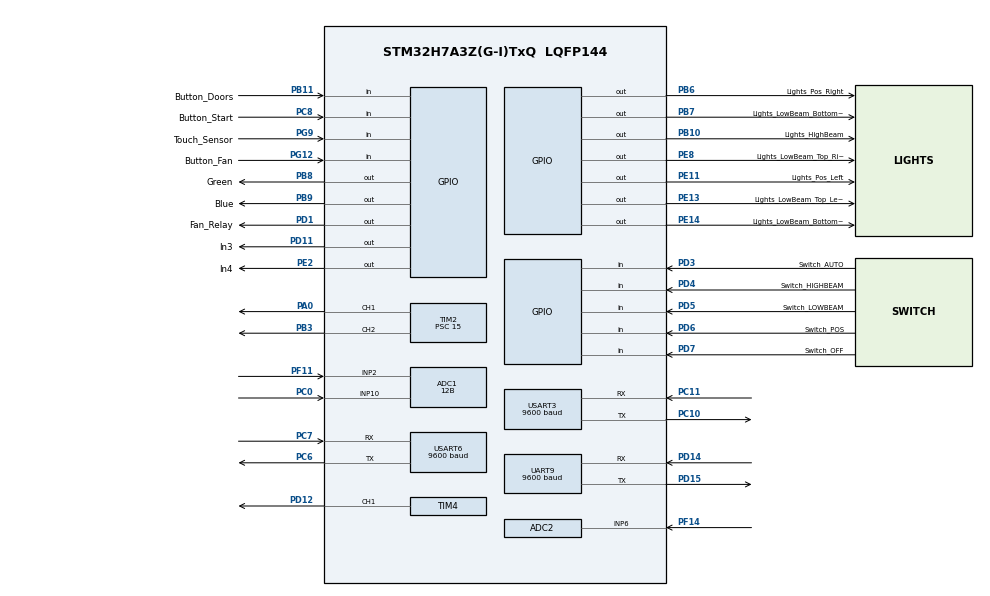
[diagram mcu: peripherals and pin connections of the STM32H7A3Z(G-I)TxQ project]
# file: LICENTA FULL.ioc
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ADC1.Channel-1\#ChannelRegularConversion=ADC_CHANNEL_2
ADC1.Channel-2\#ChannelRegularConversion=ADC_CHANNEL_10
ADC1.ContinuousConvMode=DISABLE
ADC1.ConversionDataManagement=ADC_CONVERSIONDATA_DMA_CIRCULAR
ADC1.NbrOfConversion=2
ADC1.NbrOfConversionFlag=1
ADC1.OffsetNumber-1\#ChannelRegularConversion=ADC_OFFSET_NONE
ADC1.OffsetNumber-2\#ChannelRegularConversion=ADC_OFFSET_NONE
ADC1.OffsetSignedSaturation-1\#ChannelRegularConversion=DISABLE
ADC1.Rank-1\#ChannelRegularConversion=1
ADC1.Rank-2\#ChannelRegularConversion=2
ADC1.Resolution=ADC_RESOLUTION_12B
ADC1.SamplingTime-1\#ChannelRegularConversion=ADC_SAMPLETIME_1CYCLE_5
ADC1.SamplingTime-2\#ChannelRegularConversion=ADC_SAMPLETIME_1CYCLE_5
ADC1.master=1
ADC2.Channel-0\#ChannelRegularConversion=ADC_CHANNEL_6
ADC2.ContinuousConvMode=ENABLE
ADC2.NbrOfConversion=1
ADC2.NbrOfConversionFlag=1
ADC2.OffsetNumber-0\#ChannelRegularConversion=ADC_OFFSET_NONE
ADC2.OffsetSignedSaturation-0\#ChannelRegularConversion=DISABLE
ADC2.Rank-0\#ChannelRegularConversion=1
ADC2.Resolution=ADC_RESOLUTION_12B
ADC2.SamplingTime-0\#ChannelRegularConversion=ADC_SAMPLETIME_1CYCLE_5
Dma.ADC1.0.Direction=DMA_PERIPH_TO_MEMORY
Dma.ADC1.0.EventEnable=DISABLE
Dma.ADC1.0.FIFOMode=DMA_FIFOMODE_DISABLE
Dma.ADC1.0.Instance=DMA1_Stream1
Dma.ADC1.0.MemDataAlignment=DMA_MDATAALIGN_HALFWORD
Dma.ADC1.0.MemInc=DMA_MINC_ENABLE
Dma.ADC1.0.Mode=DMA_CIRCULAR
Dma.ADC1.0.PeriphDataAlignment=DMA_PDATAALIGN_HALFWORD
Dma.ADC1.0.PeriphInc=DMA_PINC_DISABLE
Dma.ADC1.0.Polarity=HAL_DMAMUX_REQ_GEN_RISING
Dma.ADC1.0.Priority=DMA_PRIORITY_LOW
Dma.ADC1.0.RequestNumber=1
Dma.ADC1.0.SignalID=NONE
Dma.ADC1.0.SyncEnable=DISABLE
Dma.ADC1.0.SyncPolarity=HAL_DMAMUX_SYNC_NO_EVENT
Dma.ADC1.0.SyncRequestNumber=1
Dma.ADC1.0.SyncSignalID=NONE
Dma.Request0=ADC1
Dma.Request1=USART3_RX
Dma.Request2=USART6_RX
Dma.USART3_RX.1.Direction=DMA_PERIPH_TO_MEMORY
Dma.USART3_RX.1.EventEnable=DISABLE
Dma.USART3_RX.1.FIFOMode=DMA_FIFOMODE_DISABLE
Dma.USART3_RX.1.Instance=DMA1_Stream2
Dma.USART3_RX.1.MemDataAlignment=DMA_MDATAALIGN_BYTE
Dma.USART3_RX.1.MemInc=DMA_MINC_ENABLE
Dma.USART3_RX.1.Mode=DMA_NORMAL
Dma.USART3_RX.1.PeriphDataAlignment=DMA_PDATAALIGN_BYTE
Dma.USART3_RX.1.PeriphInc=DMA_PINC_DISABLE
Dma.USART3_RX.1.Polarity=HAL_DMAMUX_REQ_GEN_RISING
Dma.USART3_RX.1.Priority=DMA_PRIORITY_LOW
Dma.USART3_RX.1.RequestNumber=1
Dma.USART3_RX.1.SignalID=NONE
Dma.USART3_RX.1.SyncEnable=DISABLE
Dma.USART3_RX.1.SyncPolarity=HAL_DMAMUX_SYNC_NO_EVENT
Dma.USART3_RX.1.SyncRequestNumber=1
Dma.USART3_RX.1.SyncSignalID=NONE
Dma.USART6_RX.2.Direction=DMA_PERIPH_TO_MEMORY
Dma.USART6_RX.2.EventEnable=DISABLE
Dma.USART6_RX.2.FIFOMode=DMA_FIFOMODE_DISABLE
Dma.USART6_RX.2.Instance=DMA1_Stream0
Dma.USART6_RX.2.MemDataAlignment=DMA_MDATAALIGN_BYTE
Dma.USART6_RX.2.MemInc=DMA_MINC_ENABLE
Dma.USART6_RX.2.Mode=DMA_CIRCULAR
Dma.USART6_RX.2.PeriphDataAlignment=DMA_PDATAALIGN_BYTE
Dma.USART6_RX.2.PeriphInc=DMA_PINC_DISABLE
Dma.USART6_RX.2.Polarity=HAL_DMAMUX_REQ_GEN_RISING
Dma.USART6_RX.2.Priority=DMA_PRIORITY_LOW
Dma.USART6_RX.2.RequestNumber=1
Dma.USART6_RX.2.SignalID=NONE
Dma.USART6_RX.2.SyncEnable=DISABLE
Dma.USART6_RX.2.SyncPolarity=HAL_DMAMUX_SYNC_NO_EVENT
Dma.USART6_RX.2.SyncRequestNumber=1
Dma.USART6_RX.2.SyncSignalID=NONE
FREERTOS.Tasks01=defaultTask,24,128,StartDefaultTask,Default,NULL,Dynamic,NULL,NULL
Mcu.Family=STM32H7
Mcu.Name=STM32H7A3Z(G-I)TxQ
Mcu.Package=LQFP144
NVIC.DMA1_Stream0_IRQn=true\:5\:0\:false\:false\:true\:true\:false\:true\:true
NVIC.DMA1_Stream1_IRQn=true\:5\:0\:false\:false\:true\:true\:false\:true\:true
NVIC.DMA1_Stream2_IRQn=true\:5\:0\:false\:false\:true\:true\:false\:true\:true
NVIC.PriorityGroup=NVIC_PRIORITYGROUP_4
NVIC.USART3_IRQn=true\:5\:0\:false\:false\:true\:true\:true\:true\:true
PA0.Signal=S_TIM2_CH1_ETR
PB10.GPIO_Label=Lights_HighBeam
PB10.Signal=GPIO_Output
PB11.GPIO_Label=Button_Doors
PB11.GPIO_PuPd=GPIO_PULLDOWN
PB11.Signal=GPIO_Input
PB3.Signal=S_TIM2_CH2
PB6.GPIO_Label=Lights_Pos_Right
PB6.Signal=GPIO_Output
PB7.GPIO_Label=Lights_LowBeam_Bottom_Right
PB7.Signal=GPIO_Output
PB8.GPIO_Label=Green
PB8.Signal=GPIO_Output
PB9.GPIO_Label=Blue
PB9.Signal=GPIO_Output
PC0.Signal=ADCx_INP10
PC10.Mode=Asynchronous
PC10.Signal=USART3_TX
PC11.Mode=Asynchronous
PC11.Signal=USART3_RX
PC6.Mode=Asynchronous
PC6.Signal=USART6_TX
PC7.Mode=Asynchronous
PC7.Signal=USART6_RX
PC8.GPIO_Label=Button_Start
PC8.GPIO_PuPd=GPIO_PULLDOWN
PC8.Signal=GPIO_Input
PD1.GPIO_Label=Fan_Relay
PD1.Signal=GPIO_Output
PD11.GPIO_Label=In3
PD11.Signal=GPIO_Output
PD12.Signal=S_TIM4_CH1
PD14.Mode=Asynchronous
PD14.Signal=UART9_RX
PD15.Mode=Asynchronous
PD15.Signal=UART9_TX
PD3.GPIO_Label=Switch_AUTO
PD3.GPIO_PuPd=GPIO_PULLDOWN
PD3.Signal=GPIO_Input
PD4.GPIO_Label=Switch_HIGHBEAM
PD4.GPIO_PuPd=GPIO_PULLDOWN
PD4.Signal=GPIO_Input
PD5.GPIO_Label=Switch_LOWBEAM
PD5.GPIO_PuPd=GPIO_PULLDOWN
PD5.Signal=GPIO_Input
PD6.GPIO_Label=Switch_POS
PD6.GPIO_PuPd=GPIO_PULLDOWN
PD6.Signal=GPIO_Input
PD7.GPIO_Label=Switch_OFF
PD7.GPIO_PuPd=GPIO_PULLDOWN
PD7.Signal=GPIO_Input
PE11.GPIO_Label=Lights_Pos_Left
PE11.Signal=GPIO_Output
PE13.GPIO_Label=Lights_LowBeam_Top_Left
PE13.Signal=GPIO_Output
PE14.GPIO_Label=Lights_LowBeam_Bottom_Left
PE14.Signal=GPIO_Output
PE2.GPIO_Label=In4
PE2.Signal=GPIO_Output
PE8.GPIO_Label=Lights_LowBeam_Top_Right
PE8.Signal=GPIO_Output
PF11.Mode=IN2-Single-Ended
PF11.Signal=ADC1_INP2
PF14.Mode=IN6-Single-Ended
PF14.Signal=ADC2_INP6
PG12.GPIO_Label=Button_Fan
PG12.GPIO_PuPd=GPIO_PULLDOWN
PG12.Signal=GPIO_Input
PG9.GPIO_Label=Touch_Sensor
PG9.Signal=GPIO_Input
PH0-OSC_IN.Mode=HSE-External-Oscillator
PH0-OSC_IN.Signal=RCC_OSC_IN
PH1-OSC_OUT.Mode=HSE-External-Oscillator
PH1-OSC_OUT.Signal=RCC_OSC_OUT
ProjectManager.HeapSize=0x200
ProjectManager.StackSize=0x400
ProjectManager.TargetToolchain=STM32CubeIDE
RCC.ADCFreq_Value=42666666.666666664
RCC.APB1Freq_Value=16000000
RCC.APB2Freq_Value=16000000
RCC.APB3Freq_Value=16000000
RCC.APB4Freq_Value=16000000
RCC.CDCPRE=RCC_SYSCLK_DIV4
RCC.CortexFreq_Value=16000000
RCC.DIVM2=4
RCC.DIVN2=8
RCC.DIVP2=3
RCC.HCLKFreq_Value=16000000
RCC.PLL2FRACN=0
RCC.SYSCLKFreq_VALUE=64000000
RCC.USBFreq_Value=129000000
SH.ADCx_INP10.0=ADC1_INP10,IN10-Single-Ended
SH.S_TIM2_CH1_ETR.0=TIM2_CH1,PWM Generation1 CH1
SH.S_TIM2_CH2.0=TIM2_CH2,PWM Generation2 CH2
SH.S_TIM4_CH1.0=TIM4_CH1,PWM Generation1 CH1
TIM2.Channel-PWM\ Generation1\ CH1=TIM_CHANNEL_1
TIM2.Channel-PWM\ Generation2\ CH2=TIM_CHANNEL_2
TIM2.Period=9999
TIM2.Prescaler=15
TIM4.Channel-PWM\ Generation1\ CH1=TIM_CHANNEL_1
TIM4.Period=1023
TIM4.Prescaler=15
UART9.BaudRate=9600
USART3.BaudRate=9600
USART3.Mode=MODE_RX
USART3.VirtualMode-Asynchronous=VM_ASYNC
USART6.BaudRate=9600
USART6.VirtualMode-Asynchronous=VM_ASYNC
VP_FREERTOS_VS_CMSIS_V2.Mode=CMSIS_V2
board=custom

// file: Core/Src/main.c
/* USER CODE BEGIN Header */
/**
  ******************************************************************************
  * @file           : main.c
  * @brief          : Main program body
  ******************************************************************************
  * @attention
  *
  * Copyright (c) 2023 STMicroelectronics.
  * All rights reserved.
  *
  * This software is licensed under terms that can be found in the LICENSE file
  * in the root directory of this software component.
  * If no LICENSE file comes with this software, it is provided AS-IS.
  *
  ******************************************************************************
  */
/* USER CODE END Header */
#include "main.h"
#include "cmsis_os.h"

ADC_HandleTypeDef hadc1;
ADC_HandleTypeDef hadc2;
DMA_HandleTypeDef hdma_adc1;

TIM_HandleTypeDef htim2;
TIM_HandleTypeDef htim4;

UART_HandleTypeDef huart9;
UART_HandleTypeDef huart3;
UART_HandleTypeDef huart6;
DMA_HandleTypeDef hdma_usart3_rx;
DMA_HandleTypeDef hdma_usart6_rx;

/* Definitions for defaultTask */
osThreadId_t defaultTaskHandle;
const osThreadAttr_t defaultTask_attributes = {
  .name = "defaultTask",
  .stack_size = 128 * 4,
  .priority = (osPriority_t) osPriorityNormal,
};

void SystemClock_Config(void);
void PeriphCommonClock_Config(void);
static void MX_GPIO_Init(void);
static void MX_DMA_Init(void);
static void MX_TIM2_Init(void);
static void MX_ADC1_Init(void);
static void MX_ADC2_Init(void);
static void MX_USART3_UART_Init(void);
static void MX_UART9_Init(void);
static void MX_USART6_UART_Init(void);
static void MX_TIM4_Init(void);
void StartDefaultTask(void *argument);

int main(void)
{

  /* MCU Configuration--------------------------------------------------------*/

  /* Reset of all peripherals, Initializes the Flash interface and the Systick. */
  HAL_Init();

  /* Configure the system clock */
  SystemClock_Config();

/* Configure the peripherals common clocks */
  PeriphCommonClock_Config();

  /* Initialize all configured peripherals */
  MX_GPIO_Init();
  MX_DMA_Init();
  MX_TIM2_Init();
  MX_ADC1_Init();
  MX_ADC2_Init();
  MX_USART3_UART_Init();
  MX_UART9_Init();
  MX_USART6_UART_Init();
  MX_TIM4_Init();

  /* Init scheduler */
  osKernelInitialize();

  /* Create the thread(s) */
  /* creation of defaultTask */
  defaultTaskHandle = osThreadNew(StartDefaultTask, NULL, &defaultTask_attributes);

  /* Start scheduler */
  osKernelStart();
  /* We should never get here as control is now taken by the scheduler */
  /* Infinite loop */
  while (1)
  {

  }
}

void SystemClock_Config(void)
{
  RCC_OscInitTypeDef RCC_OscInitStruct = {0};
  RCC_ClkInitTypeDef RCC_ClkInitStruct = {0};

  /*AXI clock gating */
  RCC->CKGAENR = 0xFFFFFFFF;

  /** Supply configuration update enable
  */
  HAL_PWREx_ConfigSupply(PWR_DIRECT_SMPS_SUPPLY);

  /** Configure the main internal regulator output voltage
  */
  __HAL_PWR_VOLTAGESCALING_CONFIG(PWR_REGULATOR_VOLTAGE_SCALE3);

  while(!__HAL_PWR_GET_FLAG(PWR_FLAG_VOSRDY)) {}

  /** Macro to configure the PLL clock source
  */
  __HAL_RCC_PLL_PLLSOURCE_CONFIG(RCC_PLLSOURCE_HSI);

  /** Initializes the RCC Oscillators according to the specified parameters
  * in the RCC_OscInitTypeDef structure.
  */
  RCC_OscInitStruct.OscillatorType = RCC_OSCILLATORTYPE_HSI;
  RCC_OscInitStruct.HSIState = RCC_HSI_DIV1;
  RCC_OscInitStruct.HSICalibrationValue = 64;
  RCC_OscInitStruct.PLL.PLLState = RCC_PLL_NONE;
  if (HAL_RCC_OscConfig(&RCC_OscInitStruct) != HAL_OK)
  {
    Error_Handler();
  }

  /** Initializes the CPU, AHB and APB buses clocks
  */
  RCC_ClkInitStruct.ClockType = RCC_CLOCKTYPE_HCLK|RCC_CLOCKTYPE_SYSCLK
                              |RCC_CLOCKTYPE_PCLK1|RCC_CLOCKTYPE_PCLK2
                              |RCC_CLOCKTYPE_D3PCLK1|RCC_CLOCKTYPE_D1PCLK1;
  RCC_ClkInitStruct.SYSCLKSource = RCC_SYSCLKSOURCE_HSI;
  RCC_ClkInitStruct.SYSCLKDivider = RCC_SYSCLK_DIV4;
  RCC_ClkInitStruct.AHBCLKDivider = RCC_HCLK_DIV1;
  RCC_ClkInitStruct.APB3CLKDivider = RCC_APB3_DIV1;
  RCC_ClkInitStruct.APB1CLKDivider = RCC_APB1_DIV1;
  RCC_ClkInitStruct.APB2CLKDivider = RCC_APB2_DIV1;
  RCC_ClkInitStruct.APB4CLKDivider = RCC_APB4_DIV1;

  if (HAL_RCC_ClockConfig(&RCC_ClkInitStruct, FLASH_LATENCY_0) != HAL_OK)
  {
    Error_Handler();
  }
}

void PeriphCommonClock_Config(void)
{
  RCC_PeriphCLKInitTypeDef PeriphClkInitStruct = {0};

  /** Initializes the peripherals clock
  */
  PeriphClkInitStruct.PeriphClockSelection = RCC_PERIPHCLK_ADC;
  PeriphClkInitStruct.PLL2.PLL2M = 4;
  PeriphClkInitStruct.PLL2.PLL2N = 8;
  PeriphClkInitStruct.PLL2.PLL2P = 3;
  PeriphClkInitStruct.PLL2.PLL2Q = 2;
  PeriphClkInitStruct.PLL2.PLL2R = 2;
  PeriphClkInitStruct.PLL2.PLL2RGE = RCC_PLL2VCIRANGE_3;
  PeriphClkInitStruct.PLL2.PLL2VCOSEL = RCC_PLL2VCOWIDE;
  PeriphClkInitStruct.PLL2.PLL2FRACN = 0;
  PeriphClkInitStruct.AdcClockSelection = RCC_ADCCLKSOURCE_PLL2;
  if (HAL_RCCEx_PeriphCLKConfig(&PeriphClkInitStruct) != HAL_OK)
  {
    Error_Handler();
  }
}

static void MX_ADC1_Init(void)
{

  ADC_MultiModeTypeDef multimode = {0};
  ADC_ChannelConfTypeDef sConfig = {0};

  /** Common config
  */
  hadc1.Instance = ADC1;
  hadc1.Init.ClockPrescaler = ADC_CLOCK_ASYNC_DIV1;
  hadc1.Init.Resolution = ADC_RESOLUTION_12B;
  hadc1.Init.ScanConvMode = ADC_SCAN_ENABLE;
  hadc1.Init.EOCSelection = ADC_EOC_SINGLE_CONV;
  hadc1.Init.LowPowerAutoWait = DISABLE;
  hadc1.Init.ContinuousConvMode = DISABLE;
  hadc1.Init.NbrOfConversion = 2;
  hadc1.Init.DiscontinuousConvMode = DISABLE;
  hadc1.Init.ExternalTrigConv = ADC_SOFTWARE_START;
  hadc1.Init.ExternalTrigConvEdge = ADC_EXTERNALTRIGCONVEDGE_NONE;
  hadc1.Init.ConversionDataManagement = ADC_CONVERSIONDATA_DMA_CIRCULAR;
  hadc1.Init.Overrun = ADC_OVR_DATA_PRESERVED;
  hadc1.Init.LeftBitShift = ADC_LEFTBITSHIFT_NONE;
  hadc1.Init.OversamplingMode = DISABLE;
  if (HAL_ADC_Init(&hadc1) != HAL_OK)
  {
    Error_Handler();
  }

  /** Configure the ADC multi-mode
  */
  multimode.Mode = ADC_MODE_INDEPENDENT;
  if (HAL_ADCEx_MultiModeConfigChannel(&hadc1, &multimode) != HAL_OK)
  {
    Error_Handler();
  }

  /** Configure Regular Channel
  */
  sConfig.Channel = ADC_CHANNEL_2;
  sConfig.Rank = ADC_REGULAR_RANK_1;
  sConfig.SamplingTime = ADC_SAMPLETIME_1CYCLE_5;
  sConfig.SingleDiff = ADC_SINGLE_ENDED;
  sConfig.OffsetNumber = ADC_OFFSET_NONE;
  sConfig.Offset = 0;
  sConfig.OffsetSignedSaturation = DISABLE;
  if (HAL_ADC_ConfigChannel(&hadc1, &sConfig) != HAL_OK)
  {
    Error_Handler();
  }

  /** Configure Regular Channel
  */
  sConfig.Channel = ADC_CHANNEL_10;
  sConfig.Rank = ADC_REGULAR_RANK_2;
  if (HAL_ADC_ConfigChannel(&hadc1, &sConfig) != HAL_OK)
  {
    Error_Handler();
  }

}

static void MX_ADC2_Init(void)
{

  ADC_ChannelConfTypeDef sConfig = {0};

  /** Common config
  */
  hadc2.Instance = ADC2;
  hadc2.Init.ClockPrescaler = ADC_CLOCK_ASYNC_DIV1;
  hadc2.Init.Resolution = ADC_RESOLUTION_12B;
  hadc2.Init.ScanConvMode = ADC_SCAN_DISABLE;
  hadc2.Init.EOCSelection = ADC_EOC_SINGLE_CONV;
  hadc2.Init.LowPowerAutoWait = DISABLE;
  hadc2.Init.ContinuousConvMode = ENABLE;
  hadc2.Init.NbrOfConversion = 1;
  hadc2.Init.DiscontinuousConvMode = DISABLE;
  hadc2.Init.ExternalTrigConv = ADC_SOFTWARE_START;
  hadc2.Init.ExternalTrigConvEdge = ADC_EXTERNALTRIGCONVEDGE_NONE;
  hadc2.Init.ConversionDataManagement = ADC_CONVERSIONDATA_DR;
  hadc2.Init.Overrun = ADC_OVR_DATA_PRESERVED;
  hadc2.Init.LeftBitShift = ADC_LEFTBITSHIFT_NONE;
  hadc2.Init.OversamplingMode = DISABLE;
  if (HAL_ADC_Init(&hadc2) != HAL_OK)
  {
    Error_Handler();
  }

  /** Configure Regular Channel
  */
  sConfig.Channel = ADC_CHANNEL_6;
  sConfig.Rank = ADC_REGULAR_RANK_1;
  sConfig.SamplingTime = ADC_SAMPLETIME_1CYCLE_5;
  sConfig.SingleDiff = ADC_SINGLE_ENDED;
  sConfig.OffsetNumber = ADC_OFFSET_NONE;
  sConfig.Offset = 0;
  sConfig.OffsetSignedSaturation = DISABLE;
  if (HAL_ADC_ConfigChannel(&hadc2, &sConfig) != HAL_OK)
  {
    Error_Handler();
  }

}

static void MX_TIM2_Init(void)
{

  TIM_MasterConfigTypeDef sMasterConfig = {0};
  TIM_OC_InitTypeDef sConfigOC = {0};

  htim2.Instance = TIM2;
  htim2.Init.Prescaler = 15;
  htim2.Init.CounterMode = TIM_COUNTERMODE_UP;
  htim2.Init.Period = 9999;
  htim2.Init.ClockDivision = TIM_CLOCKDIVISION_DIV1;
  htim2.Init.AutoReloadPreload = TIM_AUTORELOAD_PRELOAD_DISABLE;
  if (HAL_TIM_PWM_Init(&htim2) != HAL_OK)
  {
    Error_Handler();
  }
  sMasterConfig.MasterOutputTrigger = TIM_TRGO_RESET;
  sMasterConfig.MasterSlaveMode = TIM_MASTERSLAVEMODE_DISABLE;
  if (HAL_TIMEx_MasterConfigSynchronization(&htim2, &sMasterConfig) != HAL_OK)
  {
    Error_Handler();
  }
  sConfigOC.OCMode = TIM_OCMODE_PWM1;
  sConfigOC.Pulse = 0;
  sConfigOC.OCPolarity = TIM_OCPOLARITY_HIGH;
  sConfigOC.OCFastMode = TIM_OCFAST_DISABLE;
  if (HAL_TIM_PWM_ConfigChannel(&htim2, &sConfigOC, TIM_CHANNEL_1) != HAL_OK)
  {
    Error_Handler();
  }
  if (HAL_TIM_PWM_ConfigChannel(&htim2, &sConfigOC, TIM_CHANNEL_2) != HAL_OK)
  {
    Error_Handler();
  }
  HAL_TIM_MspPostInit(&htim2);

}

static void MX_TIM4_Init(void)
{

  TIM_MasterConfigTypeDef sMasterConfig = {0};
  TIM_OC_InitTypeDef sConfigOC = {0};

  htim4.Instance = TIM4;
  htim4.Init.Prescaler = 15;
  htim4.Init.CounterMode = TIM_COUNTERMODE_UP;
  htim4.Init.Period = 1023;
  htim4.Init.ClockDivision = TIM_CLOCKDIVISION_DIV1;
  htim4.Init.AutoReloadPreload = TIM_AUTORELOAD_PRELOAD_DISABLE;
  if (HAL_TIM_PWM_Init(&htim4) != HAL_OK)
  {
    Error_Handler();
  }
  sMasterConfig.MasterOutputTrigger = TIM_TRGO_RESET;
  sMasterConfig.MasterSlaveMode = TIM_MASTERSLAVEMODE_DISABLE;
  if (HAL_TIMEx_MasterConfigSynchronization(&htim4, &sMasterConfig) != HAL_OK)
  {
    Error_Handler();
  }
  sConfigOC.OCMode = TIM_OCMODE_PWM1;
  sConfigOC.Pulse = 0;
  sConfigOC.OCPolarity = TIM_OCPOLARITY_HIGH;
  sConfigOC.OCFastMode = TIM_OCFAST_DISABLE;
  if (HAL_TIM_PWM_ConfigChannel(&htim4, &sConfigOC, TIM_CHANNEL_1) != HAL_OK)
  {
    Error_Handler();
  }
  HAL_TIM_MspPostInit(&htim4);

}

static void MX_UART9_Init(void)
{

  huart9.Instance = UART9;
  huart9.Init.BaudRate = 9600;
  huart9.Init.WordLength = UART_WORDLENGTH_8B;
  huart9.Init.StopBits = UART_STOPBITS_1;
  huart9.Init.Parity = UART_PARITY_NONE;
  huart9.Init.Mode = UART_MODE_TX_RX;
  huart9.Init.HwFlowCtl = UART_HWCONTROL_NONE;
  huart9.Init.OverSampling = UART_OVERSAMPLING_16;
  huart9.Init.OneBitSampling = UART_ONE_BIT_SAMPLE_DISABLE;
  huart9.Init.ClockPrescaler = UART_PRESCALER_DIV1;
  huart9.AdvancedInit.AdvFeatureInit = UART_ADVFEATURE_NO_INIT;
  if (HAL_UART_Init(&huart9) != HAL_OK)
  {
    Error_Handler();
  }
  if (HAL_UARTEx_SetTxFifoThreshold(&huart9, UART_TXFIFO_THRESHOLD_1_8) != HAL_OK)
  {
    Error_Handler();
  }
  if (HAL_UARTEx_SetRxFifoThreshold(&huart9, UART_RXFIFO_THRESHOLD_1_8) != HAL_OK)
  {
    Error_Handler();
  }
  if (HAL_UARTEx_DisableFifoMode(&huart9) != HAL_OK)
  {
    Error_Handler();
  }

}

static void MX_USART3_UART_Init(void)
{

  huart3.Instance = USART3;
  huart3.Init.BaudRate = 9600;
  huart3.Init.WordLength = UART_WORDLENGTH_8B;
  huart3.Init.StopBits = UART_STOPBITS_1;
  huart3.Init.Parity = UART_PARITY_NONE;
  huart3.Init.Mode = UART_MODE_RX;
  huart3.Init.HwFlowCtl = UART_HWCONTROL_NONE;
  huart3.Init.OverSampling = UART_OVERSAMPLING_16;
  huart3.Init.OneBitSampling = UART_ONE_BIT_SAMPLE_DISABLE;
  huart3.Init.ClockPrescaler = UART_PRESCALER_DIV1;
  huart3.AdvancedInit.AdvFeatureInit = UART_ADVFEATURE_NO_INIT;
  if (HAL_UART_Init(&huart3) != HAL_OK)
  {
    Error_Handler();
  }
  if (HAL_UARTEx_SetTxFifoThreshold(&huart3, UART_TXFIFO_THRESHOLD_1_8) != HAL_OK)
  {
    Error_Handler();
  }
  if (HAL_UARTEx_SetRxFifoThreshold(&huart3, UART_RXFIFO_THRESHOLD_1_8) != HAL_OK)
  {
    Error_Handler();
  }
  if (HAL_UARTEx_DisableFifoMode(&huart3) != HAL_OK)
  {
    Error_Handler();
  }

}

static void MX_USART6_UART_Init(void)
{

  huart6.Instance = USART6;
  huart6.Init.BaudRate = 9600;
  huart6.Init.WordLength = UART_WORDLENGTH_8B;
  huart6.Init.StopBits = UART_STOPBITS_1;
  huart6.Init.Parity = UART_PARITY_NONE;
  huart6.Init.Mode = UART_MODE_TX_RX;
  huart6.Init.HwFlowCtl = UART_HWCONTROL_NONE;
  huart6.Init.OverSampling = UART_OVERSAMPLING_16;
  huart6.Init.OneBitSampling = UART_ONE_BIT_SAMPLE_DISABLE;
  huart6.Init.ClockPrescaler = UART_PRESCALER_DIV1;
  huart6.AdvancedInit.AdvFeatureInit = UART_ADVFEATURE_NO_INIT;
  if (HAL_UART_Init(&huart6) != HAL_OK)
  {
    Error_Handler();
  }
  if (HAL_UARTEx_SetTxFifoThreshold(&huart6, UART_TXFIFO_THRESHOLD_1_8) != HAL_OK)
  {
    Error_Handler();
  }
  if (HAL_UARTEx_SetRxFifoThreshold(&huart6, UART_RXFIFO_THRESHOLD_1_8) != HAL_OK)
  {
    Error_Handler();
  }
  if (HAL_UARTEx_DisableFifoMode(&huart6) != HAL_OK)
  {
    Error_Handler();
  }

}

static void MX_DMA_Init(void)
{

  /* DMA controller clock enable */
  __HAL_RCC_DMA1_CLK_ENABLE();

  /* DMA interrupt init */
  /* DMA1_Stream0_IRQn interrupt configuration */
  HAL_NVIC_SetPriority(DMA1_Stream0_IRQn, 5, 0);
  HAL_NVIC_EnableIRQ(DMA1_Stream0_IRQn);
  /* DMA1_Stream1_IRQn interrupt configuration */
  HAL_NVIC_SetPriority(DMA1_Stream1_IRQn, 5, 0);
  HAL_NVIC_EnableIRQ(DMA1_Stream1_IRQn);
  /* DMA1_Stream2_IRQn interrupt configuration */
  HAL_NVIC_SetPriority(DMA1_Stream2_IRQn, 5, 0);
  HAL_NVIC_EnableIRQ(DMA1_Stream2_IRQn);

}

static void MX_GPIO_Init(void)
{
  GPIO_InitTypeDef GPIO_InitStruct = {0};

  /* GPIO Ports Clock Enable */
  __HAL_RCC_GPIOE_CLK_ENABLE();
  __HAL_RCC_GPIOH_CLK_ENABLE();
  __HAL_RCC_GPIOC_CLK_ENABLE();
  __HAL_RCC_GPIOA_CLK_ENABLE();
  __HAL_RCC_GPIOF_CLK_ENABLE();
  __HAL_RCC_GPIOB_CLK_ENABLE();
  __HAL_RCC_GPIOD_CLK_ENABLE();
  __HAL_RCC_GPIOG_CLK_ENABLE();

  /*Configure GPIO pin Output Level */
  HAL_GPIO_WritePin(GPIOE, In4_Pin|Lights_LowBeam_Top_Right_Pin|Lights_Pos_Left_Pin|Lights_LowBeam_Top_Left_Pin
                          |Lights_LowBeam_Bottom_Left_Pin, GPIO_PIN_RESET);

  /*Configure GPIO pin Output Level */
  HAL_GPIO_WritePin(GPIOB, Lights_HighBeam_Pin|Lights_Pos_Right_Pin|Lights_LowBeam_Bottom_Right_Pin|Green_Pin
                          |Blue_Pin, GPIO_PIN_RESET);

  /*Configure GPIO pin Output Level */
  HAL_GPIO_WritePin(GPIOD, In3_Pin|Fan_Relay_Pin, GPIO_PIN_RESET);

  /*Configure GPIO pins : In4_Pin Lights_LowBeam_Top_Right_Pin Lights_Pos_Left_Pin Lights_LowBeam_Top_Left_Pin
                           Lights_LowBeam_Bottom_Left_Pin */
  GPIO_InitStruct.Pin = In4_Pin|Lights_LowBeam_Top_Right_Pin|Lights_Pos_Left_Pin|Lights_LowBeam_Top_Left_Pin
                          |Lights_LowBeam_Bottom_Left_Pin;
  GPIO_InitStruct.Mode = GPIO_MODE_OUTPUT_PP;
  GPIO_InitStruct.Pull = GPIO_NOPULL;
  GPIO_InitStruct.Speed = GPIO_SPEED_FREQ_LOW;
  HAL_GPIO_Init(GPIOE, &GPIO_InitStruct);

  /*Configure GPIO pins : Lights_HighBeam_Pin Lights_Pos_Right_Pin Lights_LowBeam_Bottom_Right_Pin Green_Pin
                           Blue_Pin */
  GPIO_InitStruct.Pin = Lights_HighBeam_Pin|Lights_Pos_Right_Pin|Lights_LowBeam_Bottom_Right_Pin|Green_Pin
                          |Blue_Pin;
  GPIO_InitStruct.Mode = GPIO_MODE_OUTPUT_PP;
  GPIO_InitStruct.Pull = GPIO_NOPULL;
  GPIO_InitStruct.Speed = GPIO_SPEED_FREQ_LOW;
  HAL_GPIO_Init(GPIOB, &GPIO_InitStruct);

  /*Configure GPIO pin : Button_Doors_Pin */
  GPIO_InitStruct.Pin = Button_Doors_Pin;
  GPIO_InitStruct.Mode = GPIO_MODE_INPUT;
  GPIO_InitStruct.Pull = GPIO_PULLDOWN;
  HAL_GPIO_Init(Button_Doors_GPIO_Port, &GPIO_InitStruct);

  /*Configure GPIO pins : In3_Pin Fan_Relay_Pin */
  GPIO_InitStruct.Pin = In3_Pin|Fan_Relay_Pin;
  GPIO_InitStruct.Mode = GPIO_MODE_OUTPUT_PP;
  GPIO_InitStruct.Pull = GPIO_NOPULL;
  GPIO_InitStruct.Speed = GPIO_SPEED_FREQ_LOW;
  HAL_GPIO_Init(GPIOD, &GPIO_InitStruct);

  /*Configure GPIO pin : Button_Start_Pin */
  GPIO_InitStruct.Pin = Button_Start_Pin;
  GPIO_InitStruct.Mode = GPIO_MODE_INPUT;
  GPIO_InitStruct.Pull = GPIO_PULLDOWN;
  HAL_GPIO_Init(Button_Start_GPIO_Port, &GPIO_InitStruct);

  /*Configure GPIO pins : Switch_AUTO_Pin Switch_HIGHBEAM_Pin Switch_LOWBEAM_Pin Switch_POS_Pin
                           Switch_OFF_Pin */
  GPIO_InitStruct.Pin = Switch_AUTO_Pin|Switch_HIGHBEAM_Pin|Switch_LOWBEAM_Pin|Switch_POS_Pin
                          |Switch_OFF_Pin;
  GPIO_InitStruct.Mode = GPIO_MODE_INPUT;
  GPIO_InitStruct.Pull = GPIO_PULLDOWN;
  HAL_GPIO_Init(GPIOD, &GPIO_InitStruct);

  /*Configure GPIO pin : Touch_Sensor_Pin */
  GPIO_InitStruct.Pin = Touch_Sensor_Pin;
  GPIO_InitStruct.Mode = GPIO_MODE_INPUT;
  GPIO_InitStruct.Pull = GPIO_NOPULL;
  HAL_GPIO_Init(Touch_Sensor_GPIO_Port, &GPIO_InitStruct);

  /*Configure GPIO pin : Button_Fan_Pin */
  GPIO_InitStruct.Pin = Button_Fan_Pin;
  GPIO_InitStruct.Mode = GPIO_MODE_INPUT;
  GPIO_InitStruct.Pull = GPIO_PULLDOWN;
  HAL_GPIO_Init(Button_Fan_GPIO_Port, &GPIO_InitStruct);

}

void StartDefaultTask(void *argument)
{
  /* USER CODE BEGIN 5 */
  static uint8_t isInitDone = 0u;

	  for(;;)
	    {
		  	if(0u == isInitDone)
		  	{
		  		isInitDone = 1u;
		  		Start_Init();
		  	}

		  	if(isInitDone == 1u)
		  	{

	  	  	Start_TaskCyclicEvent();

		  	}
	  		osDelay(100);
	    }
	  vTaskDelete( NULL );

  /* Infinite loop */
  /* USER CODE END 5 */
}

void Error_Handler(void)
{
  __disable_irq();
  while (1)
  {
  }
}
